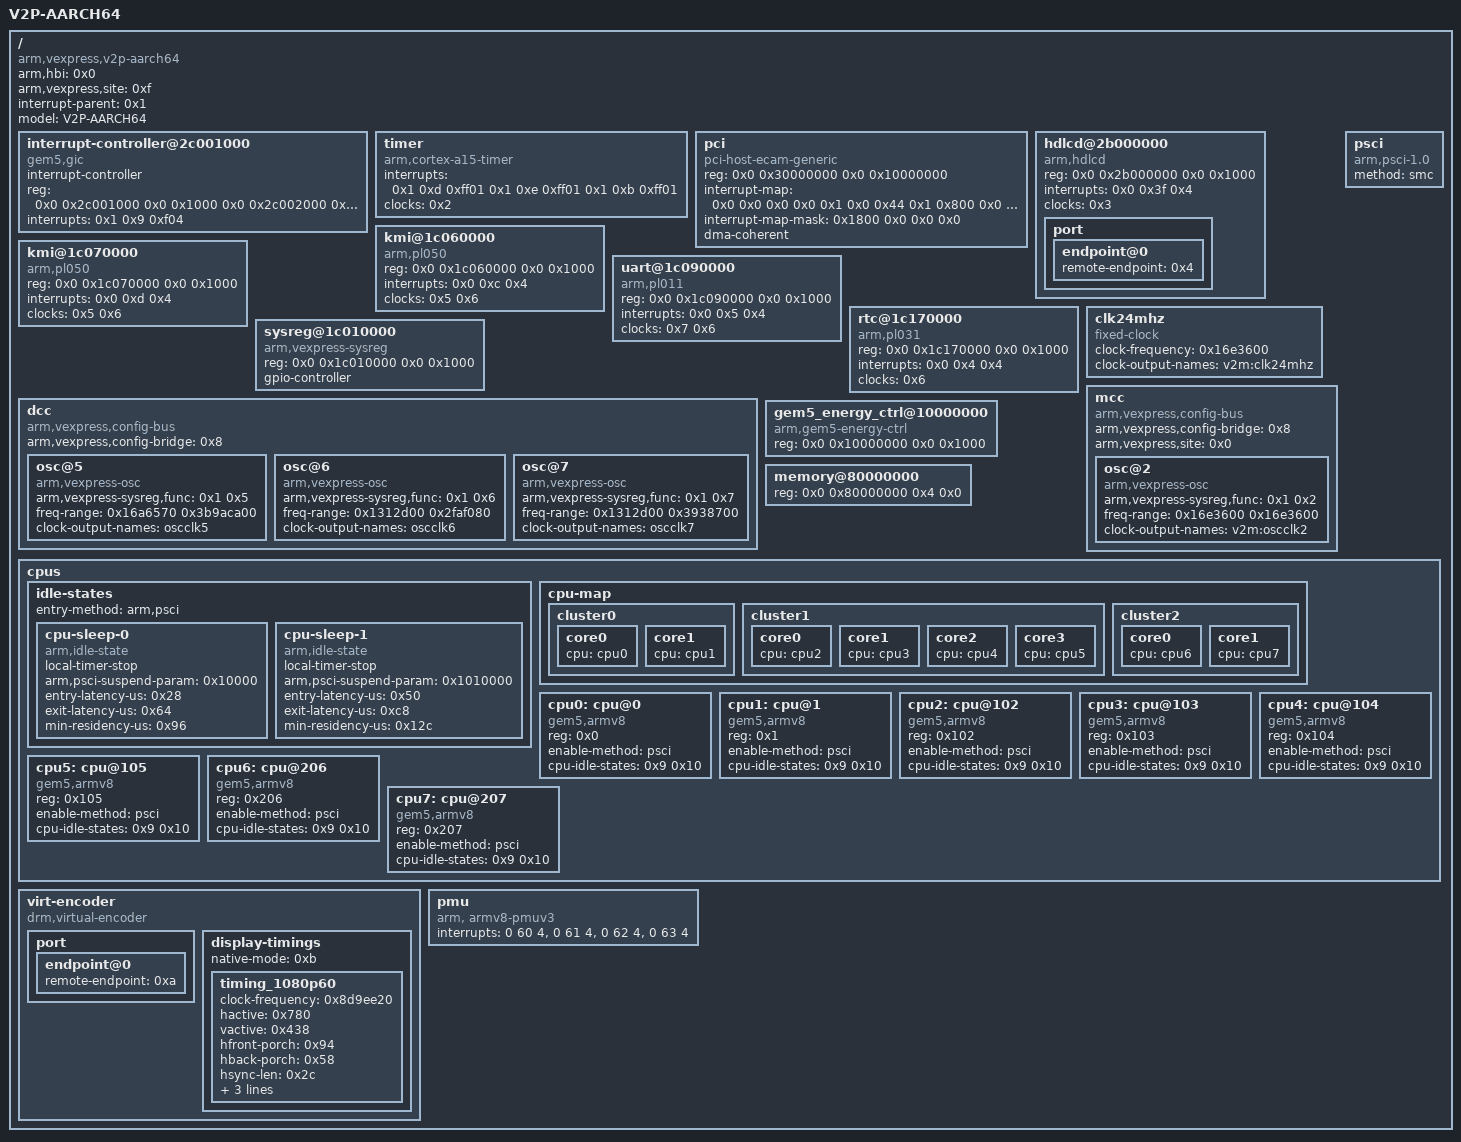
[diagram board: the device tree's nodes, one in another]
/dts-v1/;

/memreserve/	0x0000000080000000 0x0000000000010000;
/ {
	arm,hbi = <0x0>;
	arm,vexpress,site = <0xf>;
	interrupt-parent = <0x1>;
	#address-cells = <0x2>;
	#size-cells = <0x2>;
	model = "V2P-AARCH64";
	compatible = "arm,vexpress,v2p-aarch64", "arm,vexpress";

	interrupt-controller@2c001000 {
		compatible = "gem5,gic", "arm,gic-400";
		#interrupt-cells = <0x3>;
		#address-cells = <0x0>;
		interrupt-controller;
		reg = <0x0 0x2c001000 0x0 0x1000 0x0 0x2c002000 0x0 0x1000 0x0 0x2c004000 0x0 0x2000 0x0 0x2c006000 0x0 0x2000>;
		interrupts = <0x1 0x9 0xf04>;
		linux,phandle = <0x1>;
		phandle = <0x1>;
	};

	timer {
		compatible = "arm,cortex-a15-timer", "arm,armv7-timer";
		interrupts = <0x1 0xd 0xff01 0x1 0xe 0xff01 0x1 0xb 0xff01>;
		clocks = <0x2>;
		clock-names = "apb_pclk";
	};

	pci {
		compatible = "pci-host-ecam-generic";
		device_type = "pci";
		#address-cells = <0x3>;
		#size-cells = <0x2>;
		#interrupt-cells = <0x1>;
		reg = <0x0 0x30000000 0x0 0x10000000>;
		ranges = <0x1000000 0x0 0x0 0x0 0x2f000000 0x0 0x10000 0x2000000 0x0 0x40000000 0x0 0x40000000 0x0 0x40000000>;
		interrupt-map = <0x0 0x0 0x0 0x0 0x1 0x0 0x44 0x1 0x800 0x0 0x0 0x0 0x1 0x0 0x45 0x1 0x1000 0x0 0x0 0x0 0x1 0x0 0x46 0x1 0x1800 0x0 0x0 0x0 0x1 0x0 0x47 0x1>;
		interrupt-map-mask = <0x1800 0x0 0x0 0x0>;
		dma-coherent;
	};

	hdlcd@2b000000 {
		compatible = "arm,hdlcd";
		reg = <0x0 0x2b000000 0x0 0x1000>;
		interrupts = <0x0 0x3f 0x4>;
		clocks = <0x3>;
		clock-names = "pxlclk";
		status = "ok";

		port {

			endpoint@0 {
				remote-endpoint = <0x4>;
				linux,phandle = <0xa>;
				phandle = <0xa>;
			};
		};
	};

	kmi@1c060000 {
		compatible = "arm,pl050", "arm,primecell";
		reg = <0x0 0x1c060000 0x0 0x1000>;
		interrupts = <0x0 0xc 0x4>;
		clocks = <0x5 0x6>;
		clock-names = "KMIREFCLK", "apb_pclk";
	};

	kmi@1c070000 {
		compatible = "arm,pl050", "arm,primecell";
		reg = <0x0 0x1c070000 0x0 0x1000>;
		interrupts = <0x0 0xd 0x4>;
		clocks = <0x5 0x6>;
		clock-names = "KMIREFCLK", "apb_pclk";
	};

	uart@1c090000 {
		compatible = "arm,pl011", "arm,primecell";
		reg = <0x0 0x1c090000 0x0 0x1000>;
		interrupts = <0x0 0x5 0x4>;
		clocks = <0x7 0x6>;
		clock-names = "uartclk", "apb_pclk";
	};

	rtc@1c170000 {
		compatible = "arm,pl031", "arm,primecell";
		reg = <0x0 0x1c170000 0x0 0x1000>;
		interrupts = <0x0 0x4 0x4>;
		clocks = <0x6>;
		clock-names = "apb_pclk";
	};

	clk24mhz {
		compatible = "fixed-clock";
		#clock-cells = <0x0>;
		clock-frequency = <0x16e3600>;
		clock-output-names = "v2m:clk24mhz";
		linux,phandle = <0x5>;
		phandle = <0x5>;
	};

	sysreg@1c010000 {
		compatible = "arm,vexpress-sysreg";
		reg = <0x0 0x1c010000 0x0 0x1000>;
		gpio-controller;
		#gpio-cells = <0x2>;
		linux,phandle = <0x8>;
		phandle = <0x8>;
	};

	dcc {
		compatible = "arm,vexpress,config-bus";
		arm,vexpress,config-bridge = <0x8>;

		osc@5 {
			compatible = "arm,vexpress-osc";
			arm,vexpress-sysreg,func = <0x1 0x5>;
			freq-range = <0x16a6570 0x3b9aca00>;
			#clock-cells = <0x0>;
			clock-output-names = "oscclk5";
			linux,phandle = <0x3>;
			phandle = <0x3>;
		};

		osc@6 {
			compatible = "arm,vexpress-osc";
			arm,vexpress-sysreg,func = <0x1 0x6>;
			freq-range = <0x1312d00 0x2faf080>;
			#clock-cells = <0x0>;
			clock-output-names = "oscclk6";
			linux,phandle = <0x6>;
			phandle = <0x6>;
		};

		osc@7 {
			compatible = "arm,vexpress-osc";
			arm,vexpress-sysreg,func = <0x1 0x7>;
			freq-range = <0x1312d00 0x3938700>;
			#clock-cells = <0x0>;
			clock-output-names = "oscclk7";
			linux,phandle = <0x2>;
			phandle = <0x2>;
		};
	};

	mcc {
		compatible = "arm,vexpress,config-bus";
		arm,vexpress,config-bridge = <0x8>;
		arm,vexpress,site = <0x0>;

		osc@2 {
			compatible = "arm,vexpress-osc";
			arm,vexpress-sysreg,func = <0x1 0x2>;
			freq-range = <0x16e3600 0x16e3600>;
			#clock-cells = <0x0>;
			clock-output-names = "v2m:oscclk2";
			linux,phandle = <0x7>;
			phandle = <0x7>;
		};
	};

	gem5_energy_ctrl@10000000 {
		compatible = "arm,gem5-energy-ctrl";
		reg = <0x0 0x10000000 0x0 0x1000>;
	};

	memory@80000000 {
		device_type = "memory";
		reg = <0x0 0x80000000 0x4 0x0>;
	};

	psci {
		compatible = "arm,psci-1.0", "arm,psci-0.2";
		method = "smc";
	};

	cpus {
		#address-cells = <0x1>;
		#size-cells = <0x0>;

		idle-states {
			entry-method = "arm,psci";

			cpu-sleep-0 {
				compatible = "arm,idle-state";
				local-timer-stop;
				arm,psci-suspend-param = <0x10000>;
				entry-latency-us = <0x28>;
				exit-latency-us = <0x64>;
				min-residency-us = <0x96>;
				linux,phandle = <0x9>;
				phandle = <0x9>;
				};
			cpu-sleep-1 {
				compatible = "arm,idle-state";
				local-timer-stop;
				arm,psci-suspend-param = <0x1010000>;
				entry-latency-us = <0x50>;
				exit-latency-us = <0xc8>;
				min-residency-us = <0x12c>;
				linux,phandle = <0x10>;
				phandle = <0x10>;
				};
		};

		cpu-map {
			cluster0 {
				core0 {
					cpu = <&cpu0>;
				};

				core1 {
					cpu = <&cpu1>;
				};

			};

			cluster1 {
				core0 {
					cpu = <&cpu2>;
				};

				core1 {
					cpu = <&cpu3>;
				};

				core2 {
					cpu = <&cpu4>;
				};

				core3 {
					cpu = <&cpu5>;
				};
			};

			cluster2 {
				core0 {
					cpu = <&cpu6>;
				};

				core1 {
					cpu = <&cpu7>;
				};
			};
		};

		cpu0: cpu@0 {
			device_type = "cpu";
			compatible = "gem5,armv8", "arm,armv8";
			reg = <0x0>;
			enable-method = "psci";
			cpu-idle-states = <0x9 0x10>;
		};

		cpu1: cpu@1 {
			device_type = "cpu";
			compatible = "gem5,armv8", "arm,armv8";
			reg = <0x1>;
			enable-method = "psci";
			cpu-idle-states = <0x9 0x10>;
		};

		cpu2: cpu@102 {
			device_type = "cpu";
			compatible = "gem5,armv8", "arm,armv8";
			reg = <0x102>;
			enable-method = "psci";
			cpu-idle-states = <0x9 0x10>;
		};

		cpu3: cpu@103 {
			device_type = "cpu";
			compatible = "gem5,armv8", "arm,armv8";
			reg = <0x103>;
			enable-method = "psci";
			cpu-idle-states = <0x9 0x10>;
		};

		cpu4: cpu@104 {
			device_type = "cpu";
			compatible = "gem5,armv8", "arm,armv8";
			reg = <0x104>;
			enable-method = "psci";
			cpu-idle-states = <0x9 0x10>;
		};

		cpu5: cpu@105 {
			device_type = "cpu";
			compatible = "gem5,armv8", "arm,armv8";
			reg = <0x105>;
			enable-method = "psci";
			cpu-idle-states = <0x9 0x10>;
		};

		cpu6: cpu@206 {
			device_type = "cpu";
			compatible = "gem5,armv8", "arm,armv8";
			reg = <0x206>;
			enable-method = "psci";
			cpu-idle-states = <0x9 0x10>;
		};

		cpu7: cpu@207 {
			device_type = "cpu";
			compatible = "gem5,armv8", "arm,armv8";
			reg = <0x207>;
			enable-method = "psci";
			cpu-idle-states = <0x9 0x10>;
		};

	};

	virt-encoder {
		compatible = "drm,virtual-encoder";

		port {

			endpoint@0 {
				remote-endpoint = <0xa>;
				linux,phandle = <0x4>;
				phandle = <0x4>;
			};
		};

		display-timings {
			native-mode = <0xb>;

			timing_1080p60 {
				clock-frequency = <0x8d9ee20>;
				hactive = <0x780>;
				vactive = <0x438>;
				hfront-porch = <0x94>;
				hback-porch = <0x58>;
				hsync-len = <0x2c>;
				vfront-porch = <0x24>;
				vback-porch = <0x4>;
				vsync-len = <0x5>;
				linux,phandle = <0xb>;
				phandle = <0xb>;
			};
		};
	};

    pmu {
		compatible = "arm, armv8-pmuv3";
		interrupts = <0 60 4>,
		             <0 61 4>,
		             <0 62 4>,
		             <0 63 4>;
	};
};
